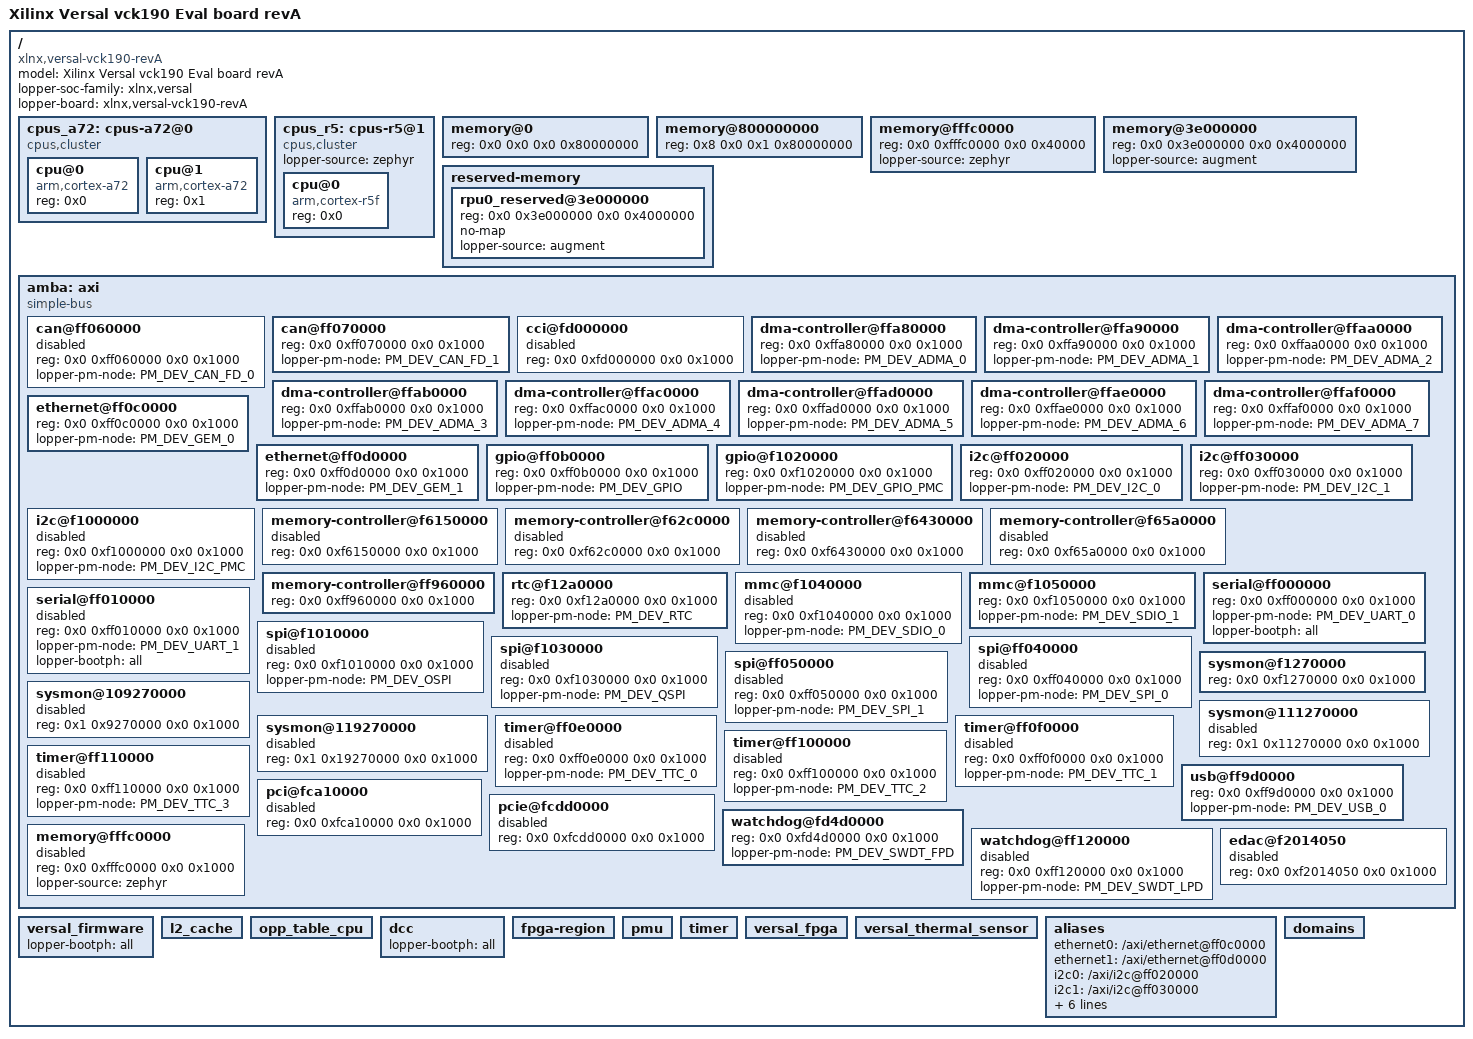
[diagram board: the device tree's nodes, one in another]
/dts-v1/;

/*
 * AUTO-GENERATED by lopper assemble_sdt from a compose_devices
 * devices YAML. Do NOT edit this file by hand — re-run the pipeline
 * with the appropriate inputs (Linux DT + optional Zephyr DT +
 * per-board augment.yaml) to regenerate.
 *
 * This is a System Device Tree intermediate. Per-device detail
 * (clocks, interrupts, vendor properties) is not reproduced from the
 * source DTs in this MVP — peripheral nodes are stubs carrying just
 * the inventory facts (reg, status, source tag, pm_node, bootph).
 * Downstream tooling (lopper domain assists) consumes this as input
 * to produce per-OS device trees.
 */

/ {
    #address-cells = <2>;
    #size-cells = <2>;
    compatible = "xlnx,versal-vck190-revA", "xlnx,versal";
    model = "Xilinx Versal vck190 Eval board revA";
    lopper-soc-family = "xlnx,versal";
    lopper-board = "xlnx,versal-vck190-revA";

    cpus_a72: cpus-a72@0 {
        #address-cells = <1>;
        #size-cells = <0>;
        compatible = "cpus,cluster";

        cpu@0 {
            device_type = "cpu";
            compatible = "arm,cortex-a72";
            reg = <0x0>;
        };

        cpu@1 {
            device_type = "cpu";
            compatible = "arm,cortex-a72";
            reg = <0x1>;
        };
    };

    cpus_r5: cpus-r5@1 {
        #address-cells = <1>;
        #size-cells = <0>;
        compatible = "cpus,cluster";
        lopper-source = "zephyr";

        cpu@0 {
            device_type = "cpu";
            compatible = "arm,cortex-r5f";
            reg = <0x0>;
        };
    };

    memory@0 {
        device_type = "memory";
        reg = <0x0 0x0 0x0 0x80000000>;
    };

    memory@800000000 {
        device_type = "memory";
        reg = <0x8 0x0 0x1 0x80000000>;
    };

    memory@fffc0000 {
        device_type = "memory";
        reg = <0x0 0xfffc0000 0x0 0x40000>;
        lopper-source = "zephyr";
    };

    memory@3e000000 {
        device_type = "memory";
        reg = <0x0 0x3e000000 0x0 0x4000000>;
        lopper-source = "augment";
    };

    reserved-memory {
        #address-cells = <2>;
        #size-cells = <2>;
        ranges;

        rpu0_reserved@3e000000 {
            reg = <0x0 0x3e000000 0x0 0x4000000>;
            no-map;
            lopper-source = "augment";
        };
    };

    amba: axi {
        compatible = "simple-bus";
        #address-cells = <2>;
        #size-cells = <2>;
        ranges;

        can@ff060000 {
            reg = <0x0 0xff060000 0x0 0x1000>;
            status = "disabled";
            lopper-pm-node = "PM_DEV_CAN_FD_0";
        };

        can@ff070000 {
            reg = <0x0 0xff070000 0x0 0x1000>;
            lopper-pm-node = "PM_DEV_CAN_FD_1";
        };

        cci@fd000000 {
            reg = <0x0 0xfd000000 0x0 0x1000>;
            status = "disabled";
        };

        dma-controller@ffa80000 {
            reg = <0x0 0xffa80000 0x0 0x1000>;
            lopper-pm-node = "PM_DEV_ADMA_0";
        };

        dma-controller@ffa90000 {
            reg = <0x0 0xffa90000 0x0 0x1000>;
            lopper-pm-node = "PM_DEV_ADMA_1";
        };

        dma-controller@ffaa0000 {
            reg = <0x0 0xffaa0000 0x0 0x1000>;
            lopper-pm-node = "PM_DEV_ADMA_2";
        };

        dma-controller@ffab0000 {
            reg = <0x0 0xffab0000 0x0 0x1000>;
            lopper-pm-node = "PM_DEV_ADMA_3";
        };

        dma-controller@ffac0000 {
            reg = <0x0 0xffac0000 0x0 0x1000>;
            lopper-pm-node = "PM_DEV_ADMA_4";
        };

        dma-controller@ffad0000 {
            reg = <0x0 0xffad0000 0x0 0x1000>;
            lopper-pm-node = "PM_DEV_ADMA_5";
        };

        dma-controller@ffae0000 {
            reg = <0x0 0xffae0000 0x0 0x1000>;
            lopper-pm-node = "PM_DEV_ADMA_6";
        };

        dma-controller@ffaf0000 {
            reg = <0x0 0xffaf0000 0x0 0x1000>;
            lopper-pm-node = "PM_DEV_ADMA_7";
        };

        ethernet@ff0c0000 {
            reg = <0x0 0xff0c0000 0x0 0x1000>;
            lopper-pm-node = "PM_DEV_GEM_0";
        };

        ethernet@ff0d0000 {
            reg = <0x0 0xff0d0000 0x0 0x1000>;
            lopper-pm-node = "PM_DEV_GEM_1";
        };

        gpio@ff0b0000 {
            reg = <0x0 0xff0b0000 0x0 0x1000>;
            lopper-pm-node = "PM_DEV_GPIO";
        };

        gpio@f1020000 {
            reg = <0x0 0xf1020000 0x0 0x1000>;
            /* label = gpiof1020000 */
            lopper-pm-node = "PM_DEV_GPIO_PMC";
        };

        i2c@ff020000 {
            reg = <0x0 0xff020000 0x0 0x1000>;
            lopper-pm-node = "PM_DEV_I2C_0";
        };

        i2c@ff030000 {
            reg = <0x0 0xff030000 0x0 0x1000>;
            lopper-pm-node = "PM_DEV_I2C_1";
        };

        i2c@f1000000 {
            reg = <0x0 0xf1000000 0x0 0x1000>;
            status = "disabled";
            lopper-pm-node = "PM_DEV_I2C_PMC";
        };

        memory-controller@f6150000 {
            reg = <0x0 0xf6150000 0x0 0x1000>;
            status = "disabled";
        };

        memory-controller@f62c0000 {
            reg = <0x0 0xf62c0000 0x0 0x1000>;
            status = "disabled";
        };

        memory-controller@f6430000 {
            reg = <0x0 0xf6430000 0x0 0x1000>;
            status = "disabled";
        };

        memory-controller@f65a0000 {
            reg = <0x0 0xf65a0000 0x0 0x1000>;
            status = "disabled";
        };

        memory-controller@ff960000 {
            reg = <0x0 0xff960000 0x0 0x1000>;
        };

        rtc@f12a0000 {
            reg = <0x0 0xf12a0000 0x0 0x1000>;
            lopper-pm-node = "PM_DEV_RTC";
        };

        mmc@f1040000 {
            reg = <0x0 0xf1040000 0x0 0x1000>;
            status = "disabled";
            lopper-pm-node = "PM_DEV_SDIO_0";
        };

        mmc@f1050000 {
            reg = <0x0 0xf1050000 0x0 0x1000>;
            lopper-pm-node = "PM_DEV_SDIO_1";
        };

        serial@ff000000 {
            reg = <0x0 0xff000000 0x0 0x1000>;
            lopper-pm-node = "PM_DEV_UART_0";
            lopper-bootph = "all";
        };

        serial@ff010000 {
            reg = <0x0 0xff010000 0x0 0x1000>;
            status = "disabled";
            lopper-pm-node = "PM_DEV_UART_1";
            lopper-bootph = "all";
        };

        spi@f1010000 {
            reg = <0x0 0xf1010000 0x0 0x1000>;
            status = "disabled";
            lopper-pm-node = "PM_DEV_OSPI";
        };

        spi@f1030000 {
            reg = <0x0 0xf1030000 0x0 0x1000>;
            status = "disabled";
            lopper-pm-node = "PM_DEV_QSPI";
        };

        spi@ff040000 {
            reg = <0x0 0xff040000 0x0 0x1000>;
            status = "disabled";
            lopper-pm-node = "PM_DEV_SPI_0";
        };

        spi@ff050000 {
            reg = <0x0 0xff050000 0x0 0x1000>;
            status = "disabled";
            lopper-pm-node = "PM_DEV_SPI_1";
        };

        sysmon@f1270000 {
            reg = <0x0 0xf1270000 0x0 0x1000>;
            /* label = sysmonf1270000 */
        };

        sysmon@109270000 {
            reg = <0x1 0x9270000 0x0 0x1000>;
            status = "disabled";
        };

        sysmon@111270000 {
            reg = <0x1 0x11270000 0x0 0x1000>;
            status = "disabled";
        };

        sysmon@119270000 {
            reg = <0x1 0x19270000 0x0 0x1000>;
            status = "disabled";
        };

        timer@ff0e0000 {
            reg = <0x0 0xff0e0000 0x0 0x1000>;
            status = "disabled";
            lopper-pm-node = "PM_DEV_TTC_0";
        };

        timer@ff0f0000 {
            reg = <0x0 0xff0f0000 0x0 0x1000>;
            status = "disabled";
            lopper-pm-node = "PM_DEV_TTC_1";
        };

        timer@ff100000 {
            reg = <0x0 0xff100000 0x0 0x1000>;
            status = "disabled";
            lopper-pm-node = "PM_DEV_TTC_2";
        };

        timer@ff110000 {
            reg = <0x0 0xff110000 0x0 0x1000>;
            status = "disabled";
            lopper-pm-node = "PM_DEV_TTC_3";
        };

        usb@ff9d0000 {
            reg = <0x0 0xff9d0000 0x0 0x1000>;
            lopper-pm-node = "PM_DEV_USB_0";
        };

        pci@fca10000 {
            reg = <0x0 0xfca10000 0x0 0x1000>;
            status = "disabled";
        };

        pcie@fcdd0000 {
            reg = <0x0 0xfcdd0000 0x0 0x1000>;
            status = "disabled";
        };

        watchdog@fd4d0000 {
            reg = <0x0 0xfd4d0000 0x0 0x1000>;
            lopper-pm-node = "PM_DEV_SWDT_FPD";
        };

        watchdog@ff120000 {
            reg = <0x0 0xff120000 0x0 0x1000>;
            status = "disabled";
            lopper-pm-node = "PM_DEV_SWDT_LPD";
        };

        edac@f2014050 {
            reg = <0x0 0xf2014050 0x0 0x1000>;
            status = "disabled";
        };

        memory@fffc0000 {
            reg = <0x0 0xfffc0000 0x0 0x1000>;
            status = "disabled";
            lopper-source = "zephyr";
        };
    };

    versal_firmware {
        lopper-bootph = "all";
    };

    l2_cache {
        /* label = l2_cache */
    };

    opp_table_cpu {
        /* label = opp_table_cpu */
    };

    dcc {
        lopper-bootph = "all";
    };

    fpga-region {
    };

    pmu {
    };

    timer {
    };

    versal_fpga {
        /* label = versal_fpga */
    };

    versal_thermal_sensor {
        /* label = versal_thermal_sensor */
    };

    aliases {
        ethernet0 = "/axi/ethernet@ff0c0000";
        ethernet1 = "/axi/ethernet@ff0d0000";
        i2c0 = "/axi/i2c@ff020000";
        i2c1 = "/axi/i2c@ff030000";
        mmc0 = "/axi/mmc@f1050000";
        rtc0 = "/axi/rtc@f12a0000";
        serial0 = "/axi/serial@ff000000";
        serial2 = "/dcc";
        spi0 = "/axi/spi@f1030000";
        usb0 = "/axi/usb@ff9d0000";
    };

    domains {
        #address-cells = <2>;
        #size-cells = <2>;
        /* Partition intent goes here. Populate via openamp,domain-v1
         * YAML overlays processed by Lopper's existing domain assists. */
    };

};
